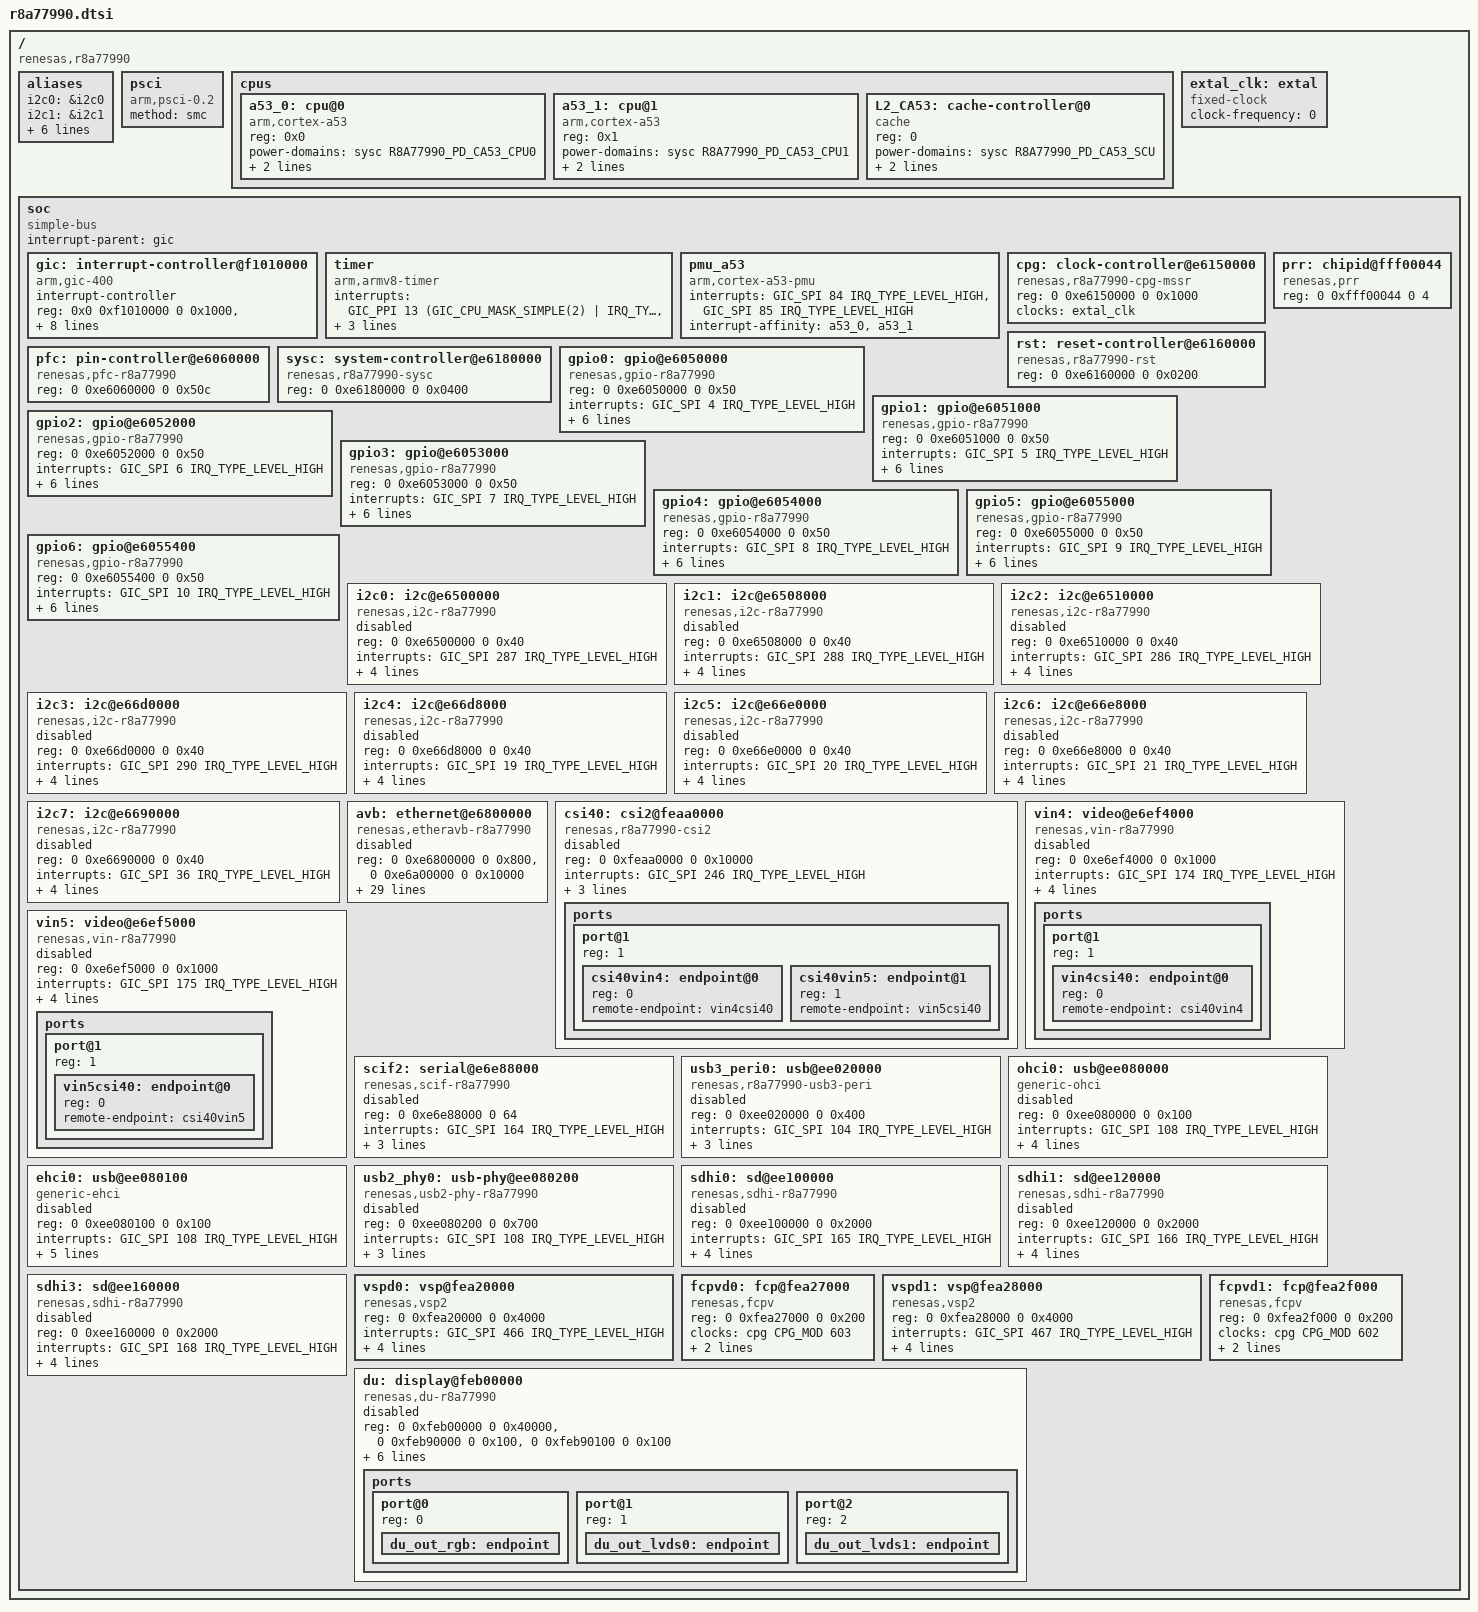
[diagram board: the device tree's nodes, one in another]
/*
 * Device Tree Source for the r8a77990 SoC
 *
 * Copyright (C) 2018 Renesas Electronics Corp.
 *
 * This file is licensed under the terms of the GNU General Public License
 * version 2.  This program is licensed "as is" without any warranty of any
 * kind, whether express or implied.
 */

#include <dt-bindings/clock/r8a77990-cpg-mssr.h>
#include <dt-bindings/interrupt-controller/arm-gic.h>
#include <dt-bindings/power/r8a77990-sysc.h>

/ {
	compatible = "renesas,r8a77990";
	#address-cells = <2>;
	#size-cells = <2>;

	aliases {
		i2c0 = &i2c0;
		i2c1 = &i2c1;
		i2c2 = &i2c2;
		i2c3 = &i2c3;
		i2c4 = &i2c4;
		i2c5 = &i2c5;
		i2c6 = &i2c6;
		i2c7 = &i2c7;
	};

	psci {
		compatible = "arm,psci-0.2";
		method = "smc";
	};

	cpus {
		#address-cells = <1>;
		#size-cells = <0>;

		a53_0: cpu@0 {
			compatible = "arm,cortex-a53", "arm,armv8";
			reg = <0x0>;
			device_type = "cpu";
			power-domains = <&sysc R8A77990_PD_CA53_CPU0>;
			next-level-cache = <&L2_CA53>;
			enable-method = "psci";
		};

		a53_1: cpu@1 {
			compatible = "arm,cortex-a53", "arm,armv8";
			reg = <0x1>;
			device_type = "cpu";
			power-domains = <&sysc R8A77990_PD_CA53_CPU1>;
			next-level-cache = <&L2_CA53>;
			enable-method = "psci";
		};

		L2_CA53: cache-controller@0 {
			compatible = "cache";
			reg = <0>;
			power-domains = <&sysc R8A77990_PD_CA53_SCU>;
			cache-unified;
			cache-level = <2>;
		};
	};

	extal_clk: extal {
		compatible = "fixed-clock";
		#clock-cells = <0>;
		/* This value must be overridden by the board */
		clock-frequency = <0>;
	};

	soc {
		compatible = "simple-bus";
		interrupt-parent = <&gic>;
		#address-cells = <2>;
		#size-cells = <2>;
		ranges;

		gic: interrupt-controller@f1010000 {
			compatible = "arm,gic-400";
			#interrupt-cells = <3>;
			#address-cells = <0>;
			interrupt-controller;
			reg = <0x0 0xf1010000 0 0x1000>,
			      <0x0 0xf1020000 0 0x20000>,
			      <0x0 0xf1040000 0 0x20000>,
			      <0x0 0xf1060000 0 0x20000>;
			interrupts = <GIC_PPI 9
					(GIC_CPU_MASK_SIMPLE(2) | IRQ_TYPE_LEVEL_HIGH)>;
			clocks = <&cpg CPG_MOD 408>;
			clock-names = "clk";
			power-domains = <&sysc R8A77990_PD_ALWAYS_ON>;
			resets = <&cpg 408>;
		};

		timer {
			compatible = "arm,armv8-timer";
			interrupts = <GIC_PPI 13
					(GIC_CPU_MASK_SIMPLE(2) | IRQ_TYPE_LEVEL_LOW)>,
				     <GIC_PPI 14
					(GIC_CPU_MASK_SIMPLE(2) | IRQ_TYPE_LEVEL_LOW)>,
				     <GIC_PPI 11
					(GIC_CPU_MASK_SIMPLE(2) | IRQ_TYPE_LEVEL_LOW)>,
				     <GIC_PPI 10
					(GIC_CPU_MASK_SIMPLE(2) | IRQ_TYPE_LEVEL_LOW)>;
		};

		pmu_a53 {
			compatible = "arm,cortex-a53-pmu";
			interrupts = <GIC_SPI 84 IRQ_TYPE_LEVEL_HIGH>,
				     <GIC_SPI 85 IRQ_TYPE_LEVEL_HIGH>;
			interrupt-affinity = <&a53_0>,
					     <&a53_1>;
		};

		cpg: clock-controller@e6150000 {
			compatible = "renesas,r8a77990-cpg-mssr";
			reg = <0 0xe6150000 0 0x1000>;
			clocks = <&extal_clk>;
			clock-names = "extal";
			#clock-cells = <2>;
			#power-domain-cells = <0>;
			#reset-cells = <1>;
		};

		rst: reset-controller@e6160000 {
			compatible = "renesas,r8a77990-rst";
			reg = <0 0xe6160000 0 0x0200>;
		};

		pfc: pin-controller@e6060000 {
			compatible = "renesas,pfc-r8a77990";
			reg = <0 0xe6060000 0 0x50c>;
		};

		prr: chipid@fff00044 {
			compatible = "renesas,prr";
			reg = <0 0xfff00044 0 4>;
		};

		sysc: system-controller@e6180000 {
			compatible = "renesas,r8a77990-sysc";
			reg = <0 0xe6180000 0 0x0400>;
			#power-domain-cells = <1>;
		};

		gpio0: gpio@e6050000 {
			compatible = "renesas,gpio-r8a77990",
				     "renesas,rcar-gen3-gpio",
				     "renesas,gpio-rcar";
			reg = <0 0xe6050000 0 0x50>;
			interrupts = <GIC_SPI 4 IRQ_TYPE_LEVEL_HIGH>;
			#gpio-cells = <2>;
			gpio-controller;
			gpio-ranges = <&pfc 0 0 18>;
			#interrupt-cells = <2>;
			interrupt-controller;
			clocks = <&cpg CPG_MOD 912>;
			power-domains = <&sysc R8A77990_PD_ALWAYS_ON>;
			resets = <&cpg 912>;
		};

		gpio1: gpio@e6051000 {
			compatible = "renesas,gpio-r8a77990",
				     "renesas,rcar-gen3-gpio",
				     "renesas,gpio-rcar";
			reg = <0 0xe6051000 0 0x50>;
			interrupts = <GIC_SPI 5 IRQ_TYPE_LEVEL_HIGH>;
			#gpio-cells = <2>;
			gpio-controller;
			gpio-ranges = <&pfc 0 32 23>;
			#interrupt-cells = <2>;
			interrupt-controller;
			clocks = <&cpg CPG_MOD 911>;
			power-domains = <&sysc R8A77990_PD_ALWAYS_ON>;
			resets = <&cpg 911>;
		};

		gpio2: gpio@e6052000 {
			compatible = "renesas,gpio-r8a77990",
				     "renesas,rcar-gen3-gpio",
				     "renesas,gpio-rcar";
			reg = <0 0xe6052000 0 0x50>;
			interrupts = <GIC_SPI 6 IRQ_TYPE_LEVEL_HIGH>;
			#gpio-cells = <2>;
			gpio-controller;
			gpio-ranges = <&pfc 0 64 26>;
			#interrupt-cells = <2>;
			interrupt-controller;
			clocks = <&cpg CPG_MOD 910>;
			power-domains = <&sysc R8A77990_PD_ALWAYS_ON>;
			resets = <&cpg 910>;
		};

		gpio3: gpio@e6053000 {
			compatible = "renesas,gpio-r8a77990",
				     "renesas,rcar-gen3-gpio",
				     "renesas,gpio-rcar";
			reg = <0 0xe6053000 0 0x50>;
			interrupts = <GIC_SPI 7 IRQ_TYPE_LEVEL_HIGH>;
			#gpio-cells = <2>;
			gpio-controller;
			gpio-ranges = <&pfc 0 96 16>;
			#interrupt-cells = <2>;
			interrupt-controller;
			clocks = <&cpg CPG_MOD 909>;
			power-domains = <&sysc R8A77990_PD_ALWAYS_ON>;
			resets = <&cpg 909>;
		};

		gpio4: gpio@e6054000 {
			compatible = "renesas,gpio-r8a77990",
				     "renesas,rcar-gen3-gpio",
				     "renesas,gpio-rcar";
			reg = <0 0xe6054000 0 0x50>;
			interrupts = <GIC_SPI 8 IRQ_TYPE_LEVEL_HIGH>;
			#gpio-cells = <2>;
			gpio-controller;
			gpio-ranges = <&pfc 0 128 11>;
			#interrupt-cells = <2>;
			interrupt-controller;
			clocks = <&cpg CPG_MOD 908>;
			power-domains = <&sysc R8A77990_PD_ALWAYS_ON>;
			resets = <&cpg 908>;
		};

		gpio5: gpio@e6055000 {
			compatible = "renesas,gpio-r8a77990",
				     "renesas,rcar-gen3-gpio",
				     "renesas,gpio-rcar";
			reg = <0 0xe6055000 0 0x50>;
			interrupts = <GIC_SPI 9 IRQ_TYPE_LEVEL_HIGH>;
			#gpio-cells = <2>;
			gpio-controller;
			gpio-ranges = <&pfc 0 160 20>;
			#interrupt-cells = <2>;
			interrupt-controller;
			clocks = <&cpg CPG_MOD 907>;
			power-domains = <&sysc R8A77990_PD_ALWAYS_ON>;
			resets = <&cpg 907>;
		};

		gpio6: gpio@e6055400 {
			compatible = "renesas,gpio-r8a77990",
				     "renesas,rcar-gen3-gpio",
				     "renesas,gpio-rcar";
			reg = <0 0xe6055400 0 0x50>;
			interrupts = <GIC_SPI 10 IRQ_TYPE_LEVEL_HIGH>;
			#gpio-cells = <2>;
			gpio-controller;
			gpio-ranges = <&pfc 0 192 18>;
			#interrupt-cells = <2>;
			interrupt-controller;
			clocks = <&cpg CPG_MOD 906>;
			power-domains = <&sysc R8A77990_PD_ALWAYS_ON>;
			resets = <&cpg 906>;
		};

		i2c0: i2c@e6500000 {
			#address-cells = <1>;
			#size-cells = <0>;
			compatible = "renesas,i2c-r8a77990",
				     "renesas,rcar-gen3-i2c";
			reg = <0 0xe6500000 0 0x40>;
			interrupts = <GIC_SPI 287 IRQ_TYPE_LEVEL_HIGH>;
			clocks = <&cpg CPG_MOD 931>;
			power-domains = <&sysc R8A77990_PD_ALWAYS_ON>;
			resets = <&cpg 931>;
			i2c-scl-internal-delay-ns = <110>;
			status = "disabled";
		};

		i2c1: i2c@e6508000 {
			#address-cells = <1>;
			#size-cells = <0>;
			compatible = "renesas,i2c-r8a77990",
				     "renesas,rcar-gen3-i2c";
			reg = <0 0xe6508000 0 0x40>;
			interrupts = <GIC_SPI 288 IRQ_TYPE_LEVEL_HIGH>;
			clocks = <&cpg CPG_MOD 930>;
			power-domains = <&sysc R8A77990_PD_ALWAYS_ON>;
			resets = <&cpg 930>;
			i2c-scl-internal-delay-ns = <6>;
			status = "disabled";
		};

		i2c2: i2c@e6510000 {
			#address-cells = <1>;
			#size-cells = <0>;
			compatible = "renesas,i2c-r8a77990",
				     "renesas,rcar-gen3-i2c";
			reg = <0 0xe6510000 0 0x40>;
			interrupts = <GIC_SPI 286 IRQ_TYPE_LEVEL_HIGH>;
			clocks = <&cpg CPG_MOD 929>;
			power-domains = <&sysc R8A77990_PD_ALWAYS_ON>;
			resets = <&cpg 929>;
			i2c-scl-internal-delay-ns = <6>;
			status = "disabled";
		};

		i2c3: i2c@e66d0000 {
			#address-cells = <1>;
			#size-cells = <0>;
			compatible = "renesas,i2c-r8a77990",
				     "renesas,rcar-gen3-i2c";
			reg = <0 0xe66d0000 0 0x40>;
			interrupts = <GIC_SPI 290 IRQ_TYPE_LEVEL_HIGH>;
			clocks = <&cpg CPG_MOD 928>;
			power-domains = <&sysc R8A77990_PD_ALWAYS_ON>;
			resets = <&cpg 928>;
			i2c-scl-internal-delay-ns = <110>;
			status = "disabled";
		};

		i2c4: i2c@e66d8000 {
			#address-cells = <1>;
			#size-cells = <0>;
			compatible = "renesas,i2c-r8a77990",
				     "renesas,rcar-gen3-i2c";
			reg = <0 0xe66d8000 0 0x40>;
			interrupts = <GIC_SPI 19 IRQ_TYPE_LEVEL_HIGH>;
			clocks = <&cpg CPG_MOD 927>;
			power-domains = <&sysc R8A77990_PD_ALWAYS_ON>;
			resets = <&cpg 927>;
			i2c-scl-internal-delay-ns = <6>;
			status = "disabled";
		};

		i2c5: i2c@e66e0000 {
			#address-cells = <1>;
			#size-cells = <0>;
			compatible = "renesas,i2c-r8a77990",
				     "renesas,rcar-gen3-i2c";
			reg = <0 0xe66e0000 0 0x40>;
			interrupts = <GIC_SPI 20 IRQ_TYPE_LEVEL_HIGH>;
			clocks = <&cpg CPG_MOD 919>;
			power-domains = <&sysc R8A77990_PD_ALWAYS_ON>;
			resets = <&cpg 919>;
			i2c-scl-internal-delay-ns = <6>;
			status = "disabled";
		};

		i2c6: i2c@e66e8000 {
			#address-cells = <1>;
			#size-cells = <0>;
			compatible = "renesas,i2c-r8a77990",
				     "renesas,rcar-gen3-i2c";
			reg = <0 0xe66e8000 0 0x40>;
			interrupts = <GIC_SPI 21 IRQ_TYPE_LEVEL_HIGH>;
			clocks = <&cpg CPG_MOD 918>;
			power-domains = <&sysc R8A77990_PD_ALWAYS_ON>;
			resets = <&cpg 918>;
			i2c-scl-internal-delay-ns = <6>;
			status = "disabled";
		};

		i2c7: i2c@e6690000 {
			#address-cells = <1>;
			#size-cells = <0>;
			compatible = "renesas,i2c-r8a77990",
				     "renesas,rcar-gen3-i2c";
			reg = <0 0xe6690000 0 0x40>;
			interrupts = <GIC_SPI 36 IRQ_TYPE_LEVEL_HIGH>;
			clocks = <&cpg CPG_MOD 1003>;
			power-domains = <&sysc R8A77990_PD_ALWAYS_ON>;
			resets = <&cpg 1003>;
			i2c-scl-internal-delay-ns = <6>;
			status = "disabled";
		};

		avb: ethernet@e6800000 {
			compatible = "renesas,etheravb-r8a77990",
				     "renesas,etheravb-rcar-gen3";
			reg = <0 0xe6800000 0 0x800>, <0 0xe6a00000 0 0x10000>;
			interrupts = <GIC_SPI 39 IRQ_TYPE_LEVEL_HIGH>,
				     <GIC_SPI 40 IRQ_TYPE_LEVEL_HIGH>,
				     <GIC_SPI 41 IRQ_TYPE_LEVEL_HIGH>,
				     <GIC_SPI 42 IRQ_TYPE_LEVEL_HIGH>,
				     <GIC_SPI 43 IRQ_TYPE_LEVEL_HIGH>,
				     <GIC_SPI 44 IRQ_TYPE_LEVEL_HIGH>,
				     <GIC_SPI 45 IRQ_TYPE_LEVEL_HIGH>,
				     <GIC_SPI 46 IRQ_TYPE_LEVEL_HIGH>,
				     <GIC_SPI 47 IRQ_TYPE_LEVEL_HIGH>,
				     <GIC_SPI 48 IRQ_TYPE_LEVEL_HIGH>,
				     <GIC_SPI 49 IRQ_TYPE_LEVEL_HIGH>,
				     <GIC_SPI 50 IRQ_TYPE_LEVEL_HIGH>,
				     <GIC_SPI 51 IRQ_TYPE_LEVEL_HIGH>,
				     <GIC_SPI 52 IRQ_TYPE_LEVEL_HIGH>,
				     <GIC_SPI 53 IRQ_TYPE_LEVEL_HIGH>,
				     <GIC_SPI 54 IRQ_TYPE_LEVEL_HIGH>,
				     <GIC_SPI 55 IRQ_TYPE_LEVEL_HIGH>,
				     <GIC_SPI 56 IRQ_TYPE_LEVEL_HIGH>,
				     <GIC_SPI 57 IRQ_TYPE_LEVEL_HIGH>,
				     <GIC_SPI 58 IRQ_TYPE_LEVEL_HIGH>,
				     <GIC_SPI 59 IRQ_TYPE_LEVEL_HIGH>,
				     <GIC_SPI 60 IRQ_TYPE_LEVEL_HIGH>,
				     <GIC_SPI 61 IRQ_TYPE_LEVEL_HIGH>,
				     <GIC_SPI 62 IRQ_TYPE_LEVEL_HIGH>,
				     <GIC_SPI 63 IRQ_TYPE_LEVEL_HIGH>;
			interrupt-names = "ch0", "ch1", "ch2", "ch3",
					  "ch4", "ch5", "ch6", "ch7",
					  "ch8", "ch9", "ch10", "ch11",
					  "ch12", "ch13", "ch14", "ch15",
					  "ch16", "ch17", "ch18", "ch19",
					  "ch20", "ch21", "ch22", "ch23",
					  "ch24";
			clocks = <&cpg CPG_MOD 812>;
			power-domains = <&sysc R8A77990_PD_ALWAYS_ON>;
			resets = <&cpg 812>;
			phy-mode = "rgmii-txid";
			#address-cells = <1>;
			#size-cells = <0>;
			status = "disabled";
		};

		csi40: csi2@feaa0000 {
			compatible = "renesas,r8a77990-csi2", "renesas,rcar-gen3-csi2";
			reg = <0 0xfeaa0000 0 0x10000>;
			interrupts = <GIC_SPI 246 IRQ_TYPE_LEVEL_HIGH>;
			clocks = <&cpg CPG_MOD 716>;
			power-domains = <&sysc R8A77990_PD_ALWAYS_ON>;
			resets = <&cpg 716>;
			status = "disabled";

			ports {
				#address-cells = <1>;
				#size-cells = <0>;

				port@1 {
					#address-cells = <1>;
					#size-cells = <0>;

					reg = <1>;

					csi40vin4: endpoint@0 {
						reg = <0>;
						remote-endpoint = <&vin4csi40>;
					};
					csi40vin5: endpoint@1 {
						reg = <1>;
						remote-endpoint = <&vin5csi40>;
					};
				};
			};
		};

		vin4: video@e6ef4000 {
			compatible = "renesas,vin-r8a77990";
			reg = <0 0xe6ef4000 0 0x1000>;
			interrupts = <GIC_SPI 174 IRQ_TYPE_LEVEL_HIGH>;
			clocks = <&cpg CPG_MOD 807>;
			power-domains = <&sysc R8A77990_PD_ALWAYS_ON>;
			resets = <&cpg 807>;
			renesas,id = <4>;
			status = "disabled";

			ports {
				#address-cells = <1>;
				#size-cells = <0>;

				port@1 {
					#address-cells = <1>;
					#size-cells = <0>;

					reg = <1>;

					vin4csi40: endpoint@0 {
						reg = <0>;
						remote-endpoint= <&csi40vin4>;
					};
				};
			};
		};

		vin5: video@e6ef5000 {
			compatible = "renesas,vin-r8a77990";
			reg = <0 0xe6ef5000 0 0x1000>;
			interrupts = <GIC_SPI 175 IRQ_TYPE_LEVEL_HIGH>;
			clocks = <&cpg CPG_MOD 806>;
			power-domains = <&sysc R8A77990_PD_ALWAYS_ON>;
			resets = <&cpg 806>;
			renesas,id = <5>;
			status = "disabled";

			ports {
				#address-cells = <1>;
				#size-cells = <0>;

				port@1 {
					#address-cells = <1>;
					#size-cells = <0>;

					reg = <1>;

					vin5csi40: endpoint@0 {
						reg = <0>;
						remote-endpoint= <&csi40vin5>;
					};
				};
			};
		};

		scif2: serial@e6e88000 {
			compatible = "renesas,scif-r8a77990",
				     "renesas,rcar-gen3-scif", "renesas,scif";
			reg = <0 0xe6e88000 0 64>;
			interrupts = <GIC_SPI 164 IRQ_TYPE_LEVEL_HIGH>;
			clocks = <&cpg CPG_MOD 310>;
			clock-names = "fck";
			power-domains = <&sysc R8A77990_PD_ALWAYS_ON>;
			resets = <&cpg 310>;
			status = "disabled";
		};

		usb3_peri0: usb@ee020000 {
			compatible = "renesas,r8a77990-usb3-peri",
				     "renesas,rcar-gen3-usb3-peri";
			reg = <0 0xee020000 0 0x400>;
			interrupts = <GIC_SPI 104 IRQ_TYPE_LEVEL_HIGH>;
			clocks = <&cpg CPG_MOD 328>;
			power-domains = <&sysc R8A77990_PD_ALWAYS_ON>;
			resets = <&cpg 328>;
			status = "disabled";
		};

		ohci0: usb@ee080000 {
			compatible = "generic-ohci";
			reg = <0 0xee080000 0 0x100>;
			interrupts = <GIC_SPI 108 IRQ_TYPE_LEVEL_HIGH>;
			clocks = <&cpg CPG_MOD 703>;
			phys = <&usb2_phy0>;
			phy-names = "usb";
			power-domains = <&sysc R8A77990_PD_ALWAYS_ON>;
			resets = <&cpg 703>;
			status = "disabled";
		};

		ehci0: usb@ee080100 {
			compatible = "generic-ehci";
			reg = <0 0xee080100 0 0x100>;
			interrupts = <GIC_SPI 108 IRQ_TYPE_LEVEL_HIGH>;
			clocks = <&cpg CPG_MOD 703>;
			phys = <&usb2_phy0>;
			phy-names = "usb";
			companion = <&ohci0>;
			power-domains = <&sysc R8A77990_PD_ALWAYS_ON>;
			resets = <&cpg 703>;
			status = "disabled";
		};

		usb2_phy0: usb-phy@ee080200 {
			compatible = "renesas,usb2-phy-r8a77990",
				     "renesas,rcar-gen3-usb2-phy";
			reg = <0 0xee080200 0 0x700>;
			interrupts = <GIC_SPI 108 IRQ_TYPE_LEVEL_HIGH>;
			clocks = <&cpg CPG_MOD 703>;
			power-domains = <&sysc R8A77990_PD_ALWAYS_ON>;
			resets = <&cpg 703>;
			#phy-cells = <0>;
			status = "disabled";
		};

		sdhi0: sd@ee100000 {
			compatible = "renesas,sdhi-r8a77990",
				     "renesas,rcar-gen3-sdhi";
			reg = <0 0xee100000 0 0x2000>;
			interrupts = <GIC_SPI 165 IRQ_TYPE_LEVEL_HIGH>;
			clocks = <&cpg CPG_MOD 314>;
			max-frequency = <200000000>;
			power-domains = <&sysc R8A77990_PD_ALWAYS_ON>;
			resets = <&cpg 314>;
			status = "disabled";
		};

		sdhi1: sd@ee120000 {
			compatible = "renesas,sdhi-r8a77990",
				     "renesas,rcar-gen3-sdhi";
			reg = <0 0xee120000 0 0x2000>;
			interrupts = <GIC_SPI 166 IRQ_TYPE_LEVEL_HIGH>;
			clocks = <&cpg CPG_MOD 313>;
			max-frequency = <200000000>;
			power-domains = <&sysc R8A77990_PD_ALWAYS_ON>;
			resets = <&cpg 313>;
			status = "disabled";
		};

		sdhi3: sd@ee160000 {
			compatible = "renesas,sdhi-r8a77990",
				     "renesas,rcar-gen3-sdhi";
			reg = <0 0xee160000 0 0x2000>;
			interrupts = <GIC_SPI 168 IRQ_TYPE_LEVEL_HIGH>;
			clocks = <&cpg CPG_MOD 311>;
			max-frequency = <200000000>;
			power-domains = <&sysc R8A77990_PD_ALWAYS_ON>;
			resets = <&cpg 311>;
			status = "disabled";
		};

		vspd0: vsp@fea20000 {
			compatible = "renesas,vsp2";
			reg = <0 0xfea20000 0 0x4000>;
			interrupts = <GIC_SPI 466 IRQ_TYPE_LEVEL_HIGH>;
			clocks = <&cpg CPG_MOD 623>;
			power-domains = <&sysc R8A77990_PD_ALWAYS_ON>;
			resets = <&cpg 623>;

			renesas,fcp = <&fcpvd0>;
		};

		fcpvd0: fcp@fea27000 {
			compatible = "renesas,fcpv";
			reg = <0 0xfea27000 0 0x200>;
			clocks = <&cpg CPG_MOD 603>;
			power-domains = <&sysc R8A77990_PD_ALWAYS_ON>;
			resets = <&cpg 603>;
		};

		vspd1: vsp@fea28000 {
			compatible = "renesas,vsp2";
			reg = <0 0xfea28000 0 0x4000>;
			interrupts = <GIC_SPI 467 IRQ_TYPE_LEVEL_HIGH>;
			clocks = <&cpg CPG_MOD 622>;
			power-domains = <&sysc R8A77990_PD_ALWAYS_ON>;
			resets = <&cpg 622>;

			renesas,fcp = <&fcpvd1>;
		};

		fcpvd1: fcp@fea2f000 {
			compatible = "renesas,fcpv";
			reg = <0 0xfea2f000 0 0x200>;
			clocks = <&cpg CPG_MOD 602>;
			power-domains = <&sysc R8A77990_PD_ALWAYS_ON>;
			resets = <&cpg 602>;
		};

		du: display@feb00000 {
			compatible = "renesas,du-r8a77990";
			reg = <0 0xfeb00000 0 0x40000>,
			      <0 0xfeb90000 0 0x100>,
			      <0 0xfeb90100 0 0x100>;
			reg-names = "du", "lvds.0", "lvds.1";
			interrupts = <GIC_SPI 256 IRQ_TYPE_LEVEL_HIGH>,
				     <GIC_SPI 268 IRQ_TYPE_LEVEL_HIGH>;
			clocks = <&cpg CPG_MOD 724>,
				 <&cpg CPG_MOD 723>,
				 <&cpg CPG_MOD 727>,
				 <&cpg CPG_MOD 727>;
			clock-names = "du.0", "du.1", "lvds.0","lvds.1";
			resets = <&cpg 724>,
				 <&cpg 724>,
				 <&cpg 727>,
				 <&cpg 726>;
			reset-names = "du.0", "du.1", "lvds.0","lvds.1";
			status = "disabled";

			vsps = <&vspd0 &vspd1>;

			ports {
				#address-cells = <1>;
				#size-cells = <0>;

				port@0 {
					reg = <0>;
					du_out_rgb: endpoint {
					};
				};
				port@1 {
					reg = <1>;
					du_out_lvds0: endpoint {
					};
				};
				port@2 {
					reg = <2>;
					du_out_lvds1: endpoint {
					};
				};
			};
		};
	};
};
